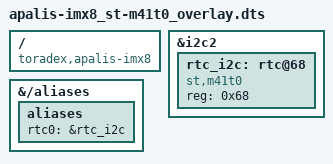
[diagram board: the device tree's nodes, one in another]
// Enable the external RTC ST m41t0

/dts-v1/;
/plugin/;

#include "dt-bindings/interrupt-controller/irq.h"
#include "dt-bindings/gpio/gpio.h"

/ {
	compatible = "toradex,apalis-imx8";
};

&i2c2 {
	#address-cells = <1>;
	#size-cells = <0>;

	/* M41T0M6 real time clock on carrier board */
	rtc_i2c: rtc@68 {
		compatible = "st,m41t0";
		reg = <0x68>;
	};
};

&{/aliases} {
	aliases {
		rtc0 = &rtc_i2c;
	};
};

